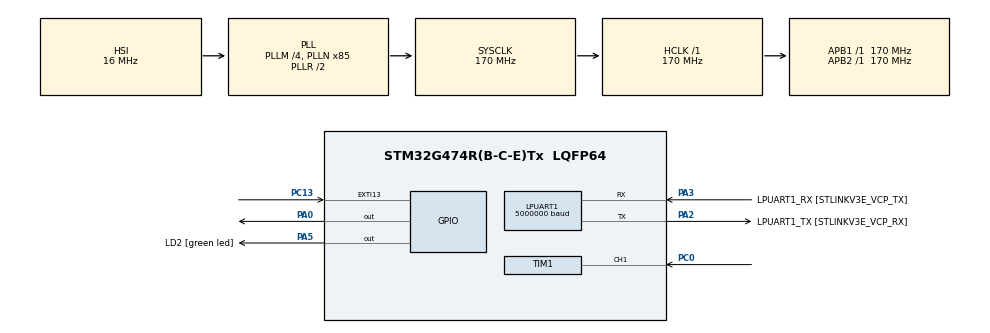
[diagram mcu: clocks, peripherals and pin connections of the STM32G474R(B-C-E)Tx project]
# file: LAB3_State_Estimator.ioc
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ARM.CMSIS.5.7.0.CMSISJjCORE=true
ARM.CMSIS.5.7.0.CMSISJjDSP=Library
Dma.LPUART1_RX.1.Direction=DMA_PERIPH_TO_MEMORY
Dma.LPUART1_RX.1.EventEnable=DISABLE
Dma.LPUART1_RX.1.Instance=DMA1_Channel2
Dma.LPUART1_RX.1.MemDataAlignment=DMA_MDATAALIGN_BYTE
Dma.LPUART1_RX.1.MemInc=DMA_MINC_ENABLE
Dma.LPUART1_RX.1.Mode=DMA_CIRCULAR
Dma.LPUART1_RX.1.PeriphDataAlignment=DMA_PDATAALIGN_BYTE
Dma.LPUART1_RX.1.PeriphInc=DMA_PINC_DISABLE
Dma.LPUART1_RX.1.Polarity=HAL_DMAMUX_REQ_GEN_RISING
Dma.LPUART1_RX.1.Priority=DMA_PRIORITY_LOW
Dma.LPUART1_RX.1.RequestNumber=1
Dma.LPUART1_RX.1.SignalID=NONE
Dma.LPUART1_RX.1.SyncEnable=DISABLE
Dma.LPUART1_RX.1.SyncPolarity=HAL_DMAMUX_SYNC_NO_EVENT
Dma.LPUART1_RX.1.SyncRequestNumber=1
Dma.LPUART1_RX.1.SyncSignalID=NONE
Dma.LPUART1_TX.0.Direction=DMA_MEMORY_TO_PERIPH
Dma.LPUART1_TX.0.EventEnable=DISABLE
Dma.LPUART1_TX.0.Instance=DMA1_Channel1
Dma.LPUART1_TX.0.MemDataAlignment=DMA_MDATAALIGN_BYTE
Dma.LPUART1_TX.0.MemInc=DMA_MINC_ENABLE
Dma.LPUART1_TX.0.Mode=DMA_NORMAL
Dma.LPUART1_TX.0.PeriphDataAlignment=DMA_PDATAALIGN_BYTE
Dma.LPUART1_TX.0.PeriphInc=DMA_PINC_DISABLE
Dma.LPUART1_TX.0.Polarity=HAL_DMAMUX_REQ_GEN_RISING
Dma.LPUART1_TX.0.Priority=DMA_PRIORITY_LOW
Dma.LPUART1_TX.0.RequestNumber=1
Dma.LPUART1_TX.0.SignalID=NONE
Dma.LPUART1_TX.0.SyncEnable=DISABLE
Dma.LPUART1_TX.0.SyncPolarity=HAL_DMAMUX_SYNC_NO_EVENT
Dma.LPUART1_TX.0.SyncRequestNumber=1
Dma.LPUART1_TX.0.SyncSignalID=NONE
Dma.Request0=LPUART1_TX
Dma.Request1=LPUART1_RX
LPUART1.BaudRate=5000000
Mcu.Family=STM32G4
Mcu.Name=STM32G474R(B-C-E)Tx
Mcu.Package=LQFP64
NVIC.DMA1_Channel1_IRQn=true\:0\:0\:false\:false\:true\:false\:true\:true
NVIC.DMA1_Channel2_IRQn=true\:0\:0\:false\:false\:true\:false\:true\:true
NVIC.EXTI15_10_IRQn=true\:0\:0\:false\:false\:true\:true\:true\:true
NVIC.LPUART1_IRQn=true\:0\:0\:false\:false\:true\:true\:true\:true
NVIC.PriorityGroup=NVIC_PRIORITYGROUP_4
NVIC.TIM1_CC_IRQn=true\:0\:0\:false\:false\:true\:true\:true\:true
NVIC.TIM3_IRQn=true\:0\:0\:false\:false\:true\:true\:true\:true
NVIC.TIM4_IRQn=true\:0\:0\:false\:false\:true\:true\:true\:true
PA0.Signal=GPIO_Output
PA13.GPIO_Label=T_SWDIO
PA13.Signal=SYS_JTMS-SWDIO
PA14.GPIO_Label=T_SWCLK
PA14.Signal=SYS_JTCK-SWCLK
PA2.GPIO_Label=LPUART1_TX [STLINKV3E_VCP_RX]
PA2.Mode=Asynchronous
PA2.Signal=LPUART1_TX
PA3.GPIO_Label=LPUART1_RX [STLINKV3E_VCP_TX]
PA3.Mode=Asynchronous
PA3.Signal=LPUART1_RX
PA5.GPIO_Label=LD2 [green led]
PA5.Signal=GPIO_Output
PB3.GPIO_Label=T_SWO
PB3.Signal=SYS_JTDO-SWO
PC0.Signal=S_TIM1_CH1
PC13.Signal=GPXTI13
PC14-OSC32_IN.GPIO_Label=RCC_OSC32_IN
PC14-OSC32_IN.Signal=RCC_OSC32_IN
PC15-OSC32_OUT.GPIO_Label=RCC_OSC32_OUT
PC15-OSC32_OUT.Signal=RCC_OSC32_OUT
PF0-OSC_IN.GPIO_Label=RCC_OSC_IN
PF0-OSC_IN.Signal=RCC_OSC_IN
PF1-OSC_OUT.GPIO_Label=RCC_OSC_OUT
PF1-OSC_OUT.Signal=RCC_OSC_OUT
ProjectManager.HeapSize=0x200
ProjectManager.StackSize=0x400
ProjectManager.TargetToolchain=STM32CubeIDE
RCC.ADC12Freq_Value=170000000
RCC.ADC345Freq_Value=170000000
RCC.AHBFreq_Value=170000000
RCC.APB1Freq_Value=170000000
RCC.APB1TimFreq_Value=170000000
RCC.APB2Freq_Value=170000000
RCC.APB2TimFreq_Value=170000000
RCC.CortexFreq_Value=170000000
RCC.EXTERNAL_CLOCK_VALUE=12288000
RCC.HCLKFreq_Value=170000000
RCC.HSE_VALUE=24000000
RCC.HSI48_VALUE=48000000
RCC.HSI_VALUE=16000000
RCC.LSE_VALUE=32768
RCC.PLLM=RCC_PLLM_DIV4
RCC.PLLN=85
RCC.RTCClockSelection=RCC_RTCCLKSOURCE_LSE
RCC.SYSCLKFreq_VALUE=170000000
RCC.SYSCLKSource=RCC_SYSCLKSOURCE_PLLCLK
RCC.USBFreq_Value=170000000
RCC.VCOOutputFreq_Value=340000000
SH.S_TIM1_CH1.0=TIM1_CH1,Input_Capture1_from_TI1
TIM1.Channel-Input_Capture1_from_TI1=TIM_CHANNEL_1
TIM1.Prescaler=169
TIM2.Prescaler=169
TIM3.PeriodNoDither=25000
TIM3.Prescaler=169
TIM3.TIM_MasterOutputTrigger=TIM_TRGO_UPDATE
TIM4.PeriodNoDither=1000
TIM4.Prescaler=169
VP_ARM.CMSIS_VS_CMSISJjCORE_5.4.0_5.7.0.Mode=CMSISJjCORE
VP_ARM.CMSIS_VS_CMSISJjDSP_1.8.0_5.7.0.Mode=CMSISJjDSP
VP_SYS_VS_DBSignals.Mode=DisableDeadBatterySignals
VP_TIM1_VS_ClockSourceINT.Mode=Internal
VP_TIM2_VS_ClockSourceINT.Mode=Internal
VP_TIM3_VS_ClockSourceINT.Mode=Internal
VP_TIM4_VS_ClockSourceINT.Mode=Internal
board=NUCLEO-G474RE

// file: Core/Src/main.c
/* USER CODE BEGIN Header */
/**
 ******************************************************************************
 * @file           : main.c
 * @brief          : Main program body
 ******************************************************************************
 * @attention
 *
 * Copyright (c) 2026 STMicroelectronics.
 * All rights reserved.
 *
 * This software is licensed under terms that can be found in the LICENSE file
 * in the root directory of this software component.
 * If no LICENSE file comes with this software, it is provided AS-IS.
 *
 ******************************************************************************
 */
/* USER CODE END Header */
#include "main.h"

/* USER CODE BEGIN Includes */
#include "kalman.h"
/* USER CODE END Includes */

/* USER CODE BEGIN PTD */
Ultrasonic TIM_Data = { 0 };
KALMAN_1D_Params Pos_cost_data[3] = { 0 };
KALMAN_Multi_Velocity_Params Velo_cost_data[3] = { 0 };

/* USER CODE END PTD */

/* USER CODE BEGIN PD */
#define UART_Header 0X0F
#define UART_Stopper 0X0A
/* USER CODE END PD */

UART_HandleTypeDef hlpuart1;
DMA_HandleTypeDef hdma_lpuart1_tx;
DMA_HandleTypeDef hdma_lpuart1_rx;

TIM_HandleTypeDef htim1;
TIM_HandleTypeDef htim2;
TIM_HandleTypeDef htim3;
TIM_HandleTypeDef htim4;

/* USER CODE BEGIN PV */
char msg_buffer[50];
int32_t buffer;
volatile uint8_t tx_ready_flag = 1;
uint8_t TxBuffer[50];
uint8_t RxBuffer[10];
uint8_t DMAstate;
int32_t Normalvalue;
float32_t data[3];
volatile int Mode;
/* USER CODE END PV */

void SystemClock_Config(void);
static void MX_GPIO_Init(void);
static void MX_DMA_Init(void);
static void MX_TIM2_Init(void);
static void MX_TIM3_Init(void);
static void MX_TIM1_Init(void);
static void MX_LPUART1_UART_Init(void);
static void MX_TIM4_Init(void);

int main(void)
{

  /* MCU Configuration--------------------------------------------------------*/

  /* Reset of all peripherals, Initializes the Flash interface and the Systick. */
  HAL_Init();

  /* Configure the system clock */
  SystemClock_Config();

  /* Initialize all configured peripherals */
  MX_GPIO_Init();
  MX_DMA_Init();
  MX_TIM2_Init();
  MX_TIM3_Init();
  MX_TIM1_Init();
  MX_LPUART1_UART_Init();
  MX_TIM4_Init();
  /* USER CODE BEGIN 2 */

	HAL_TIM_Base_Start(&htim2);
	HAL_TIM_Base_Start_IT(&htim3);
	HAL_TIM_Base_Start_IT(&htim4);
	HAL_TIM_IC_Start_IT(&htim1, TIM_CHANNEL_1);
	HAL_UART_Receive_DMA(&hlpuart1, RxBuffer, 3);

	TIM_Data.state = 1;
	buffer = 100;
	DMAstate = 1;
	Normalvalue = 100;
	Mode = 0;

	KALMAN_1D_Init(&Pos_cost_data[0], 0.001f, 0.75f); //target process measure
	KALMAN_1D_Init(&Pos_cost_data[1], 0.01f, 0.75f); //target process measure
	KALMAN_1D_Init(&Pos_cost_data[2], 0.1f, 0.75f); //target process measure
	KALMAN_Multi_Velocity_Init(&Velo_cost_data[0], 1000000.0f, 0.75f);
	KALMAN_Multi_Velocity_Init(&Velo_cost_data[1], 1100000.0f, 0.75f);
	KALMAN_Multi_Velocity_Init(&Velo_cost_data[2], 1200000.0f, 0.75f);
  /* USER CODE END 2 */

  /* Infinite loop */
	while (1) {

	}
}

void SystemClock_Config(void)
{
  RCC_OscInitTypeDef RCC_OscInitStruct = {0};
  RCC_ClkInitTypeDef RCC_ClkInitStruct = {0};

  /** Configure the main internal regulator output voltage
  */
  HAL_PWREx_ControlVoltageScaling(PWR_REGULATOR_VOLTAGE_SCALE1_BOOST);

  /** Initializes the RCC Oscillators according to the specified parameters
  * in the RCC_OscInitTypeDef structure.
  */
  RCC_OscInitStruct.OscillatorType = RCC_OSCILLATORTYPE_HSI;
  RCC_OscInitStruct.HSIState = RCC_HSI_ON;
  RCC_OscInitStruct.HSICalibrationValue = RCC_HSICALIBRATION_DEFAULT;
  RCC_OscInitStruct.PLL.PLLState = RCC_PLL_ON;
  RCC_OscInitStruct.PLL.PLLSource = RCC_PLLSOURCE_HSI;
  RCC_OscInitStruct.PLL.PLLM = RCC_PLLM_DIV4;
  RCC_OscInitStruct.PLL.PLLN = 85;
  RCC_OscInitStruct.PLL.PLLP = RCC_PLLP_DIV2;
  RCC_OscInitStruct.PLL.PLLQ = RCC_PLLQ_DIV2;
  RCC_OscInitStruct.PLL.PLLR = RCC_PLLR_DIV2;
  if (HAL_RCC_OscConfig(&RCC_OscInitStruct) != HAL_OK)
  {
    Error_Handler();
  }

  /** Initializes the CPU, AHB and APB buses clocks
  */
  RCC_ClkInitStruct.ClockType = RCC_CLOCKTYPE_HCLK|RCC_CLOCKTYPE_SYSCLK
                              |RCC_CLOCKTYPE_PCLK1|RCC_CLOCKTYPE_PCLK2;
  RCC_ClkInitStruct.SYSCLKSource = RCC_SYSCLKSOURCE_PLLCLK;
  RCC_ClkInitStruct.AHBCLKDivider = RCC_SYSCLK_DIV1;
  RCC_ClkInitStruct.APB1CLKDivider = RCC_HCLK_DIV1;
  RCC_ClkInitStruct.APB2CLKDivider = RCC_HCLK_DIV1;

  if (HAL_RCC_ClockConfig(&RCC_ClkInitStruct, FLASH_LATENCY_4) != HAL_OK)
  {
    Error_Handler();
  }
}

static void MX_LPUART1_UART_Init(void)
{

  hlpuart1.Instance = LPUART1;
  hlpuart1.Init.BaudRate = 5000000;
  hlpuart1.Init.WordLength = UART_WORDLENGTH_8B;
  hlpuart1.Init.StopBits = UART_STOPBITS_1;
  hlpuart1.Init.Parity = UART_PARITY_NONE;
  hlpuart1.Init.Mode = UART_MODE_TX_RX;
  hlpuart1.Init.HwFlowCtl = UART_HWCONTROL_NONE;
  hlpuart1.Init.OneBitSampling = UART_ONE_BIT_SAMPLE_DISABLE;
  hlpuart1.Init.ClockPrescaler = UART_PRESCALER_DIV1;
  hlpuart1.AdvancedInit.AdvFeatureInit = UART_ADVFEATURE_NO_INIT;
  if (HAL_UART_Init(&hlpuart1) != HAL_OK)
  {
    Error_Handler();
  }
  if (HAL_UARTEx_SetTxFifoThreshold(&hlpuart1, UART_TXFIFO_THRESHOLD_1_8) != HAL_OK)
  {
    Error_Handler();
  }
  if (HAL_UARTEx_SetRxFifoThreshold(&hlpuart1, UART_RXFIFO_THRESHOLD_1_8) != HAL_OK)
  {
    Error_Handler();
  }
  if (HAL_UARTEx_DisableFifoMode(&hlpuart1) != HAL_OK)
  {
    Error_Handler();
  }

}

static void MX_TIM1_Init(void)
{

  TIM_ClockConfigTypeDef sClockSourceConfig = {0};
  TIM_MasterConfigTypeDef sMasterConfig = {0};
  TIM_IC_InitTypeDef sConfigIC = {0};

  htim1.Instance = TIM1;
  htim1.Init.Prescaler = 169;
  htim1.Init.CounterMode = TIM_COUNTERMODE_UP;
  htim1.Init.Period = 65535;
  htim1.Init.ClockDivision = TIM_CLOCKDIVISION_DIV1;
  htim1.Init.RepetitionCounter = 0;
  htim1.Init.AutoReloadPreload = TIM_AUTORELOAD_PRELOAD_DISABLE;
  if (HAL_TIM_Base_Init(&htim1) != HAL_OK)
  {
    Error_Handler();
  }
  sClockSourceConfig.ClockSource = TIM_CLOCKSOURCE_INTERNAL;
  if (HAL_TIM_ConfigClockSource(&htim1, &sClockSourceConfig) != HAL_OK)
  {
    Error_Handler();
  }
  if (HAL_TIM_IC_Init(&htim1) != HAL_OK)
  {
    Error_Handler();
  }
  sMasterConfig.MasterOutputTrigger = TIM_TRGO_RESET;
  sMasterConfig.MasterOutputTrigger2 = TIM_TRGO2_RESET;
  sMasterConfig.MasterSlaveMode = TIM_MASTERSLAVEMODE_DISABLE;
  if (HAL_TIMEx_MasterConfigSynchronization(&htim1, &sMasterConfig) != HAL_OK)
  {
    Error_Handler();
  }
  sConfigIC.ICPolarity = TIM_INPUTCHANNELPOLARITY_RISING;
  sConfigIC.ICSelection = TIM_ICSELECTION_DIRECTTI;
  sConfigIC.ICPrescaler = TIM_ICPSC_DIV1;
  sConfigIC.ICFilter = 0;
  if (HAL_TIM_IC_ConfigChannel(&htim1, &sConfigIC, TIM_CHANNEL_1) != HAL_OK)
  {
    Error_Handler();
  }

}

static void MX_TIM2_Init(void)
{

  TIM_ClockConfigTypeDef sClockSourceConfig = {0};
  TIM_MasterConfigTypeDef sMasterConfig = {0};

  htim2.Instance = TIM2;
  htim2.Init.Prescaler = 169;
  htim2.Init.CounterMode = TIM_COUNTERMODE_UP;
  htim2.Init.Period = 4294967295;
  htim2.Init.ClockDivision = TIM_CLOCKDIVISION_DIV1;
  htim2.Init.AutoReloadPreload = TIM_AUTORELOAD_PRELOAD_DISABLE;
  if (HAL_TIM_Base_Init(&htim2) != HAL_OK)
  {
    Error_Handler();
  }
  sClockSourceConfig.ClockSource = TIM_CLOCKSOURCE_INTERNAL;
  if (HAL_TIM_ConfigClockSource(&htim2, &sClockSourceConfig) != HAL_OK)
  {
    Error_Handler();
  }
  sMasterConfig.MasterOutputTrigger = TIM_TRGO_RESET;
  sMasterConfig.MasterSlaveMode = TIM_MASTERSLAVEMODE_DISABLE;
  if (HAL_TIMEx_MasterConfigSynchronization(&htim2, &sMasterConfig) != HAL_OK)
  {
    Error_Handler();
  }

}

static void MX_TIM3_Init(void)
{

  TIM_ClockConfigTypeDef sClockSourceConfig = {0};
  TIM_MasterConfigTypeDef sMasterConfig = {0};

  htim3.Instance = TIM3;
  htim3.Init.Prescaler = 169;
  htim3.Init.CounterMode = TIM_COUNTERMODE_UP;
  htim3.Init.Period = 25000;
  htim3.Init.ClockDivision = TIM_CLOCKDIVISION_DIV1;
  htim3.Init.AutoReloadPreload = TIM_AUTORELOAD_PRELOAD_DISABLE;
  if (HAL_TIM_Base_Init(&htim3) != HAL_OK)
  {
    Error_Handler();
  }
  sClockSourceConfig.ClockSource = TIM_CLOCKSOURCE_INTERNAL;
  if (HAL_TIM_ConfigClockSource(&htim3, &sClockSourceConfig) != HAL_OK)
  {
    Error_Handler();
  }
  sMasterConfig.MasterOutputTrigger = TIM_TRGO_UPDATE;
  sMasterConfig.MasterSlaveMode = TIM_MASTERSLAVEMODE_DISABLE;
  if (HAL_TIMEx_MasterConfigSynchronization(&htim3, &sMasterConfig) != HAL_OK)
  {
    Error_Handler();
  }

}

static void MX_TIM4_Init(void)
{

  TIM_ClockConfigTypeDef sClockSourceConfig = {0};
  TIM_MasterConfigTypeDef sMasterConfig = {0};

  htim4.Instance = TIM4;
  htim4.Init.Prescaler = 169;
  htim4.Init.CounterMode = TIM_COUNTERMODE_UP;
  htim4.Init.Period = 1000;
  htim4.Init.ClockDivision = TIM_CLOCKDIVISION_DIV1;
  htim4.Init.AutoReloadPreload = TIM_AUTORELOAD_PRELOAD_DISABLE;
  if (HAL_TIM_Base_Init(&htim4) != HAL_OK)
  {
    Error_Handler();
  }
  sClockSourceConfig.ClockSource = TIM_CLOCKSOURCE_INTERNAL;
  if (HAL_TIM_ConfigClockSource(&htim4, &sClockSourceConfig) != HAL_OK)
  {
    Error_Handler();
  }
  sMasterConfig.MasterOutputTrigger = TIM_TRGO_RESET;
  sMasterConfig.MasterSlaveMode = TIM_MASTERSLAVEMODE_DISABLE;
  if (HAL_TIMEx_MasterConfigSynchronization(&htim4, &sMasterConfig) != HAL_OK)
  {
    Error_Handler();
  }

}

static void MX_DMA_Init(void)
{

  /* DMA controller clock enable */
  __HAL_RCC_DMAMUX1_CLK_ENABLE();
  __HAL_RCC_DMA1_CLK_ENABLE();

  /* DMA interrupt init */
  /* DMA1_Channel1_IRQn interrupt configuration */
  HAL_NVIC_SetPriority(DMA1_Channel1_IRQn, 0, 0);
  HAL_NVIC_EnableIRQ(DMA1_Channel1_IRQn);
  /* DMA1_Channel2_IRQn interrupt configuration */
  HAL_NVIC_SetPriority(DMA1_Channel2_IRQn, 0, 0);
  HAL_NVIC_EnableIRQ(DMA1_Channel2_IRQn);

}

static void MX_GPIO_Init(void)
{
  GPIO_InitTypeDef GPIO_InitStruct = {0};

  /* GPIO Ports Clock Enable */
  __HAL_RCC_GPIOC_CLK_ENABLE();
  __HAL_RCC_GPIOF_CLK_ENABLE();
  __HAL_RCC_GPIOA_CLK_ENABLE();
  __HAL_RCC_GPIOB_CLK_ENABLE();

  /*Configure GPIO pin Output Level */
  HAL_GPIO_WritePin(GPIOA, GPIO_PIN_0|LD2_Pin, GPIO_PIN_RESET);

  /*Configure GPIO pin : B1_Pin */
  GPIO_InitStruct.Pin = B1_Pin;
  GPIO_InitStruct.Mode = GPIO_MODE_IT_RISING;
  GPIO_InitStruct.Pull = GPIO_NOPULL;
  HAL_GPIO_Init(B1_GPIO_Port, &GPIO_InitStruct);

  /*Configure GPIO pins : PA0 LD2_Pin */
  GPIO_InitStruct.Pin = GPIO_PIN_0|LD2_Pin;
  GPIO_InitStruct.Mode = GPIO_MODE_OUTPUT_PP;
  GPIO_InitStruct.Pull = GPIO_NOPULL;
  GPIO_InitStruct.Speed = GPIO_SPEED_FREQ_LOW;
  HAL_GPIO_Init(GPIOA, &GPIO_InitStruct);

  /* EXTI interrupt init*/
  HAL_NVIC_SetPriority(EXTI15_10_IRQn, 0, 0);
  HAL_NVIC_EnableIRQ(EXTI15_10_IRQn);

}

/* USER CODE BEGIN 4 */
void delay() {
	{
		__HAL_TIM_SET_COUNTER(&htim1, 0);
		while (__HAL_TIM_GET_COUNTER (&htim2) < 10)
			;
	}
}

void HAL_TIM_PeriodElapsedCallback(TIM_HandleTypeDef *htim) {
	// Check if the interrupt was triggered by Timer 2
	if (htim->Instance == TIM3) {
		HAL_GPIO_TogglePin(GPIOA, GPIO_PIN_0);
		delay();
		HAL_GPIO_TogglePin(GPIOA, GPIO_PIN_0);
	}
	if (htim->Instance == TIM4) { // 1. Compute Kalman Filters
		if (Mode == 1) {
			for (int i = 0; i < 3; i++) {
				KALMAN_1D_Compute(&Pos_cost_data[i], TIM_Data.Distance);
				data[i] = Pos_cost_data[i].x;
			}
		} else if (Mode == 2) {
			for (int i = 0; i < 3; i++) {
				KALMAN_Multi_Velocity_Compute(&Velo_cost_data[i],
						(float32_t) TIM_Data.Distance);
				data[i] = Velo_cost_data[i].X[0];
			}
		} else {
			for (int i = 0; i < 3; i++) {
				data[i] = 0;
			}
		}
		uint64_t data_b[3];
		for (int i = 0; i < 3; i++) {
			double temp_d = (double) data[i];
			// This captures the raw IEEE-754 bit pattern
			data_b[i] = *(uint64_t*) &temp_d;
		}
		double dist_d = (double) TIM_Data.Distance;
		// 3. Extract raw bytes uint64_t
		uint64_t dist_b;
		dist_b = *(uint64_t*) &dist_d;
		// 4. Pack the TxBuffer (New Mapping)
		TxBuffer[0] = UART_Header; // Index 0 // Velocity 1 (Bytes 1-8)
		for (int i = 0; i < 8; i++) {
			TxBuffer[1 + i] = (uint8_t) (data_b[0] >> (8 * i));
		} // Velocity 2 (Bytes 9-16)
		for (int i = 0; i < 8; i++) {
			TxBuffer[9 + i] = (uint8_t) (data_b[1] >> (8 * i));
		} // Velocity 3 (Bytes 17-24)
		for (int i = 0; i < 8; i++) {
			TxBuffer[17 + i] = (uint8_t) (data_b[2] >> (8 * i));
		} // Distance (Bytes 25-32)
		for (int i = 0; i < 8; i++) {
			TxBuffer[25 + i] = (uint8_t) (dist_b >> (8 * i));
		}
		TxBuffer[33] = UART_Stopper; // Index 33
		HAL_GPIO_TogglePin(GPIOA, GPIO_PIN_5); // 5. Transmit 34 bytes total // (Header + 4x8 bytes + Stopper = 34)
		HAL_UART_Transmit_DMA(&hlpuart1, TxBuffer, 34);
	}
}

void HAL_TIM_IC_CaptureCallback(TIM_HandleTypeDef *htim) {
// 1. Check if the interrupt came from Timer 1
if (htim->Instance == TIM1) {
	if (TIM_Data.state == 1) {
		TIM_Data.Rising = HAL_TIM_ReadCapturedValue(&htim1,
		TIM_CHANNEL_1);
		__HAL_TIM_SET_CAPTUREPOLARITY(&htim1, TIM_CHANNEL_1,
				TIM_INPUTCHANNELPOLARITY_FALLING);
		TIM_Data.state = 2;
	} else if (TIM_Data.state == 2) {
		TIM_Data.Falling = HAL_TIM_ReadCapturedValue(&htim1,
		TIM_CHANNEL_1);
		__HAL_TIM_SET_CAPTUREPOLARITY(&htim1, TIM_CHANNEL_1,
				TIM_INPUTCHANNELPOLARITY_RISING);
		TIM_Data.state = 1;
		TIM_Data.Diff = TIM_Data.Falling - TIM_Data.Rising;
		TIM_Data.Distance = (float) TIM_Data.Diff / 58.0f;
		__HAL_TIM_SET_COUNTER(&htim1, 0);

	}
}
}

void HAL_UART_RxCpltCallback(UART_HandleTypeDef *huart) {

if (huart == &hlpuart1) {
	Mode = RxBuffer[1];
}
}
//
//	void UARTDMAConfig(){
//		HAL_UART_Receive_DMA(&hlpart1, RxBuffer ,10);
//	}
//
//	void HAL_UART_RxCpltCallback(UART_HandleTypeDef *huart){
//		if(huart == &hlpuart1){
//
//		}
//	}

/* USER CODE END 4 */

void Error_Handler(void)
{
__disable_irq();
while (1) {
}
}
